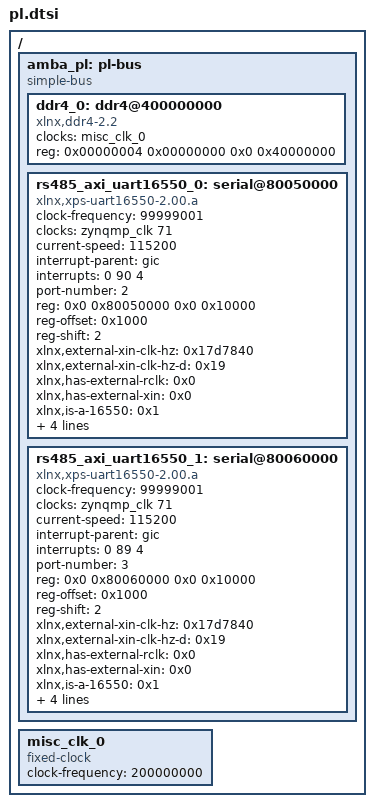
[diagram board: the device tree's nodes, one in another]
/*
 * CAUTION: This file is automatically generated by Xilinx.
 * Version: XSCT 2024.2
 * Today is: Sun Aug  9 12:07:29 2026
 */


/ {
	amba_pl: pl-bus {
		#address-cells = <2>;
		#size-cells = <2>;
		compatible = "simple-bus";
		ranges ;
		ddr4_0: ddr4@400000000 {
			clock-names = "c0_sys_clk_i";
			clocks = <&misc_clk_0>;
			compatible = "xlnx,ddr4-2.2";
			reg = <0x00000004 0x00000000 0x0 0x40000000>;
		};
		rs485_axi_uart16550_0: serial@80050000 {
			clock-frequency = <99999001>;
			clock-names = "s_axi_aclk";
			clocks = <&zynqmp_clk 71>;
			compatible = "xlnx,xps-uart16550-2.00.a", "ns16550a";
			current-speed = <115200>;
			device_type = "serial";
			interrupt-names = "ip2intc_irpt";
			interrupt-parent = <&gic>;
			interrupts = <0 90 4>;
			port-number = <2>;
			reg = <0x0 0x80050000 0x0 0x10000>;
			reg-offset = <0x1000>;
			reg-shift = <2>;
			xlnx,external-xin-clk-hz = <0x17d7840>;
			xlnx,external-xin-clk-hz-d = <0x19>;
			xlnx,has-external-rclk = <0x0>;
			xlnx,has-external-xin = <0x0>;
			xlnx,is-a-16550 = <0x1>;
			xlnx,s-axi-aclk-freq-hz-d = "99.999001";
			xlnx,sim-device = "VERSAL_AI_CORE_ES1";
			xlnx,use-modem-ports = <0x1>;
			xlnx,use-user-ports = <0x1>;
		};
		rs485_axi_uart16550_1: serial@80060000 {
			clock-frequency = <99999001>;
			clock-names = "s_axi_aclk";
			clocks = <&zynqmp_clk 71>;
			compatible = "xlnx,xps-uart16550-2.00.a", "ns16550a";
			current-speed = <115200>;
			device_type = "serial";
			interrupt-names = "ip2intc_irpt";
			interrupt-parent = <&gic>;
			interrupts = <0 89 4>;
			port-number = <3>;
			reg = <0x0 0x80060000 0x0 0x10000>;
			reg-offset = <0x1000>;
			reg-shift = <2>;
			xlnx,external-xin-clk-hz = <0x17d7840>;
			xlnx,external-xin-clk-hz-d = <0x19>;
			xlnx,has-external-rclk = <0x0>;
			xlnx,has-external-xin = <0x0>;
			xlnx,is-a-16550 = <0x1>;
			xlnx,s-axi-aclk-freq-hz-d = "99.999001";
			xlnx,sim-device = "VERSAL_AI_CORE_ES1";
			xlnx,use-modem-ports = <0x1>;
			xlnx,use-user-ports = <0x1>;
		};
	};
	misc_clk_0: misc_clk_0 {
		#clock-cells = <0>;
		clock-frequency = <200000000>;
		compatible = "fixed-clock";
	};
};
